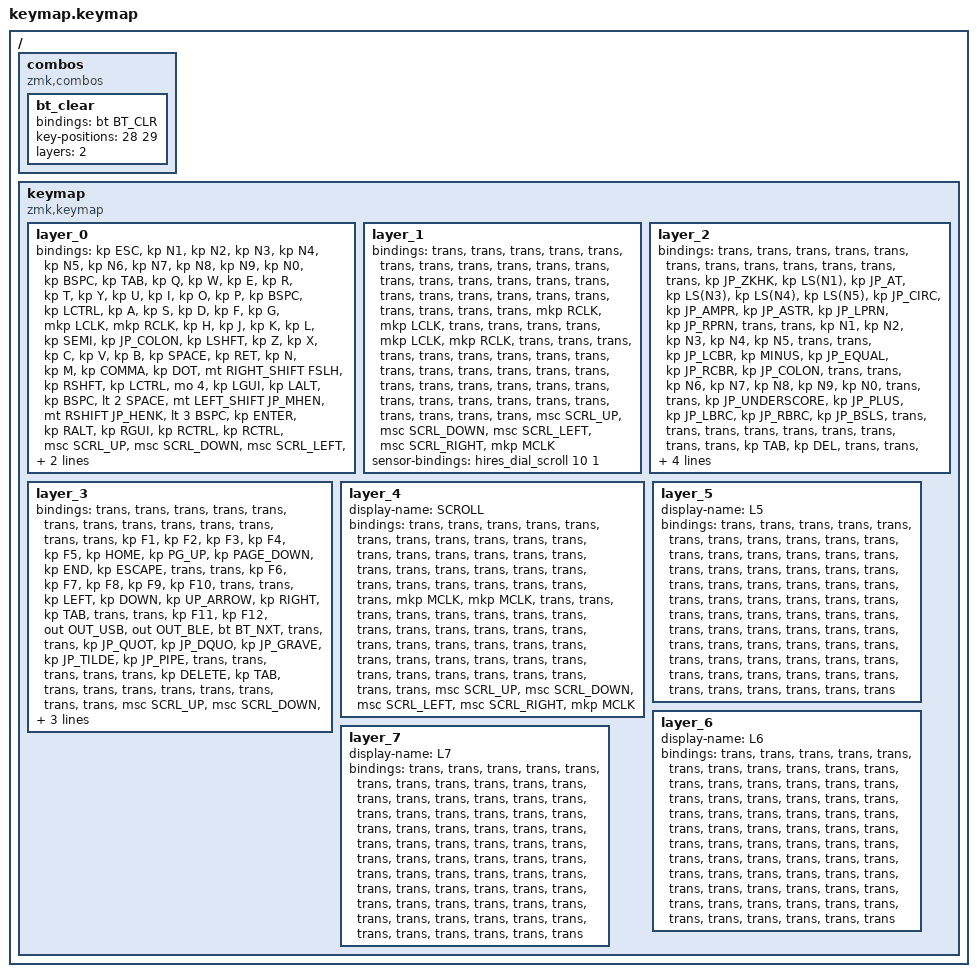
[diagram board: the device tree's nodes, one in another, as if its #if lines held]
#include <behaviors.dtsi>
#include <dt-bindings/zmk/bt.h>
#include <dt-bindings/zmk/keys.h>
#include <dt-bindings/zmk/outputs.h>
#include <dt-bindings/zmk/pointing.h>
#include "jis.h"

#if defined(TORABO_TSUKI_LP_INPUT_HIRES_DIAL)
#include <behaviors/hires_dial.dtsi>
#endif

/ {
    combos {
        compatible = "zmk,combos";

        bt_clear {
            bindings = <&bt BT_CLR>;
            key-positions = <28 29>;
            layers = <2>;
        };
    };

    keymap {
        compatible = "zmk,keymap";

        layer_0 {
            bindings = <
&kp ESC    &kp N1     &kp N2    &kp N3    &kp N4    &kp N5                                                         &kp N6       &kp N7    &kp N8     &kp N9    &kp N0                &kp BSPC
&kp TAB    &kp Q      &kp W     &kp E     &kp R     &kp T                                                          &kp Y        &kp U     &kp I      &kp O     &kp P                 &kp BSPC
&kp LCTRL   &kp A      &kp S     &kp D     &kp F     &kp G        &mkp LCLK                  &mkp RCLK              &kp H        &kp J     &kp K      &kp L     &kp SEMI              &kp JP_COLON
&kp LSHFT  &kp Z      &kp X     &kp C     &kp V     &kp B        &kp SPACE                  &kp RET                &kp N        &kp M     &kp COMMA  &kp DOT   &mt RIGHT_SHIFT FSLH  &kp RSHFT
&kp LCTRL  &mo 4      &kp LGUI  &kp LALT  &kp BSPC  &lt 2 SPACE  &mt LEFT_SHIFT JP_MHEN  &mt RSHIFT JP_HENK  &lt 3 BSPC   &kp ENTER  &kp RALT   &kp RGUI  &kp RCTRL             &kp RCTRL
#if defined(TORABO_TSUKI_LP_KSCAN_4_DIRECTION_SWITCH)
&msc SCRL_UP &msc SCRL_DOWN &msc SCRL_LEFT &msc SCRL_RIGHT &mkp MCLK
#elif defined(TORABO_TSUKI_LP_INPUT_HIRES_DIAL)
&mkp MCLK
#endif
            >;
        };

        layer_1 {
            bindings = <
&trans  &trans  &trans  &trans     &trans     &trans                  &trans  &trans     &trans     &trans  &trans  &trans
&trans  &trans  &trans  &trans     &trans     &trans                  &trans  &trans     &trans     &trans  &trans  &trans
&trans  &trans  &trans  &mkp RCLK  &mkp LCLK  &trans  &trans  &trans  &trans  &mkp LCLK  &mkp RCLK  &trans  &trans  &trans
&trans  &trans  &trans  &trans     &trans     &trans  &trans  &trans  &trans  &trans     &trans     &trans  &trans  &trans
&trans  &trans  &trans  &trans     &trans     &trans  &trans  &trans  &trans  &trans     &trans     &trans  &trans  &trans
#if defined(TORABO_TSUKI_LP_KSCAN_4_DIRECTION_SWITCH)
&msc SCRL_UP &msc SCRL_DOWN &msc SCRL_LEFT &msc SCRL_RIGHT &mkp MCLK
#elif defined(TORABO_TSUKI_LP_INPUT_HIRES_DIAL)
&mkp MCLK
#endif
            >;
        };

        layer_2 {
            bindings = <
&trans  &trans            &trans            &trans      &trans      &trans                      &trans          &trans         &trans            &trans             &trans         &trans
&kp JP_ZKHK &kp LS(N1)        &kp JP_AT         &kp LS(N3)  &kp LS(N4)  &kp LS(N5)                  &kp JP_CIRC     &kp JP_AMPR    &kp JP_ASTR       &kp JP_LPRN        &kp JP_RPRN    &trans
&trans  &kp N1            &kp N2            &kp N3      &kp N4      &kp N5      &trans  &trans  &kp JP_LCBR  &kp MINUS      &kp JP_EQUAL         &kp JP_RCBR    &kp JP_COLON      &trans
&trans  &kp N6            &kp N7            &kp N8      &kp N9      &kp N0      &trans  &trans  &kp JP_UNDERSCORE   &kp JP_PLUS  &kp JP_LBRC  &kp JP_RBRC  &kp JP_BSLS  &trans
&trans  &trans            &trans            &trans      &trans      &trans      &trans  &trans  &kp TAB         &kp DEL        &trans            &trans             &trans         &trans
#if defined(TORABO_TSUKI_LP_KSCAN_4_DIRECTION_SWITCH)
&msc SCRL_UP &msc SCRL_DOWN &msc SCRL_LEFT &msc SCRL_RIGHT &mkp MCLK
#elif defined(TORABO_TSUKI_LP_INPUT_HIRES_DIAL)
&kp C_MUTE
#endif
            >;
        };

        layer_3 {
            bindings = <
&trans  &trans   &trans   &trans        &trans        &trans                      &trans            &trans     &trans         &trans     &trans      &trans
&trans  &kp F1   &kp F2   &kp F3        &kp F4        &kp F5                      &kp HOME          &kp PG_UP  &kp PAGE_DOWN  &kp END    &kp ESCAPE  &trans
&trans  &kp F6   &kp F7   &kp F8        &kp F9        &kp F10     &trans  &trans  &kp LEFT          &kp DOWN   &kp UP_ARROW   &kp RIGHT  &kp TAB     &trans
&trans  &kp F11  &kp F12  &out OUT_USB  &out OUT_BLE  &bt BT_NXT  &trans  &trans  &kp JP_QUOT  &kp JP_DQUO    &kp JP_GRAVE      &kp JP_TILDE  &kp JP_PIPE    &trans
&trans  &trans   &trans   &trans        &kp DELETE    &kp TAB     &trans  &trans  &trans            &trans     &trans         &trans     &trans      &trans
#if defined(TORABO_TSUKI_LP_KSCAN_4_DIRECTION_SWITCH)
&msc SCRL_UP &msc SCRL_DOWN &msc SCRL_LEFT &msc SCRL_RIGHT &mkp MCLK
#elif defined(TORABO_TSUKI_LP_INPUT_HIRES_DIAL)
&hires_dial_radial_controller_button
#endif
            >;
        };

        layer_4 {
            display-name = "SCROLL";
            // このレイヤー中はトラックボール（左右とも）がスクロールになる。
            // 設定は snippets/input-listener, input-split-listener の scroller ノード。
            bindings = <
&trans  &trans  &trans  &trans  &trans  &trans                &trans  &trans  &trans  &trans  &trans  &trans  
&trans  &trans  &trans  &trans  &trans  &trans                &trans  &trans  &trans  &trans  &trans  &trans  
&trans  &trans  &trans  &trans  &trans  &trans  &mkp MCLK  &mkp MCLK  &trans  &trans  &trans  &trans  &trans  &trans
&trans  &trans  &trans  &trans  &trans  &trans  &trans  &trans  &trans  &trans  &trans  &trans  &trans  &trans  
&trans  &trans  &trans  &trans  &trans  &trans  &trans  &trans  &trans  &trans  &trans  &trans  &trans  &trans  
#if defined(TORABO_TSUKI_LP_KSCAN_4_DIRECTION_SWITCH)
&msc SCRL_UP &msc SCRL_DOWN &msc SCRL_LEFT &msc SCRL_RIGHT &mkp MCLK
#elif defined(TORABO_TSUKI_LP_INPUT_HIRES_DIAL)
&mkp MCLK
#endif
            >;
        };

        layer_5 {
            display-name = "L5";
            bindings = <
&trans  &trans  &trans  &trans  &trans  &trans                &trans  &trans  &trans  &trans  &trans  &trans  
&trans  &trans  &trans  &trans  &trans  &trans                &trans  &trans  &trans  &trans  &trans  &trans  
&trans  &trans  &trans  &trans  &trans  &trans  &trans  &trans  &trans  &trans  &trans  &trans  &trans  &trans  
&trans  &trans  &trans  &trans  &trans  &trans  &trans  &trans  &trans  &trans  &trans  &trans  &trans  &trans  
&trans  &trans  &trans  &trans  &trans  &trans  &trans  &trans  &trans  &trans  &trans  &trans  &trans  &trans  
#if defined(TORABO_TSUKI_LP_KSCAN_4_DIRECTION_SWITCH)
&trans &trans &trans &trans &trans
#elif defined(TORABO_TSUKI_LP_INPUT_HIRES_DIAL)
&trans
#endif
            >;
        };

        layer_6 {
            display-name = "L6";
            bindings = <
&trans  &trans  &trans  &trans  &trans  &trans                &trans  &trans  &trans  &trans  &trans  &trans  
&trans  &trans  &trans  &trans  &trans  &trans                &trans  &trans  &trans  &trans  &trans  &trans  
&trans  &trans  &trans  &trans  &trans  &trans  &trans  &trans  &trans  &trans  &trans  &trans  &trans  &trans  
&trans  &trans  &trans  &trans  &trans  &trans  &trans  &trans  &trans  &trans  &trans  &trans  &trans  &trans  
&trans  &trans  &trans  &trans  &trans  &trans  &trans  &trans  &trans  &trans  &trans  &trans  &trans  &trans  
#if defined(TORABO_TSUKI_LP_KSCAN_4_DIRECTION_SWITCH)
&trans &trans &trans &trans &trans
#elif defined(TORABO_TSUKI_LP_INPUT_HIRES_DIAL)
&trans
#endif
            >;
        };

        layer_7 {
            display-name = "L7";
            bindings = <
&trans  &trans  &trans  &trans  &trans  &trans                &trans  &trans  &trans  &trans  &trans  &trans  
&trans  &trans  &trans  &trans  &trans  &trans                &trans  &trans  &trans  &trans  &trans  &trans  
&trans  &trans  &trans  &trans  &trans  &trans  &trans  &trans  &trans  &trans  &trans  &trans  &trans  &trans  
&trans  &trans  &trans  &trans  &trans  &trans  &trans  &trans  &trans  &trans  &trans  &trans  &trans  &trans  
&trans  &trans  &trans  &trans  &trans  &trans  &trans  &trans  &trans  &trans  &trans  &trans  &trans  &trans  
#if defined(TORABO_TSUKI_LP_KSCAN_4_DIRECTION_SWITCH)
&trans &trans &trans &trans &trans
#elif defined(TORABO_TSUKI_LP_INPUT_HIRES_DIAL)
&trans
#endif
            >;
        };
    };
};

#if defined(TORABO_TSUKI_LP_INPUT_HIRES_DIAL)
&{/keymap/layer_0} {
    sensor-bindings = <&hires_dial_scroll 1 1>;
};

&{/keymap/layer_1} {
    sensor-bindings = <&hires_dial_scroll 10 1>;
};

&{/keymap/layer_2} {
    sensor-bindings = <&hires_dial_encoder C_VOL_UP C_VOL_DN>;
};

&{/keymap/layer_3} {
    /* Quarter-speed Radial Controller motion: output/input = 1/4. */
    sensor-bindings = <&hires_dial_radial_controller 4 1>;
};
#endif
